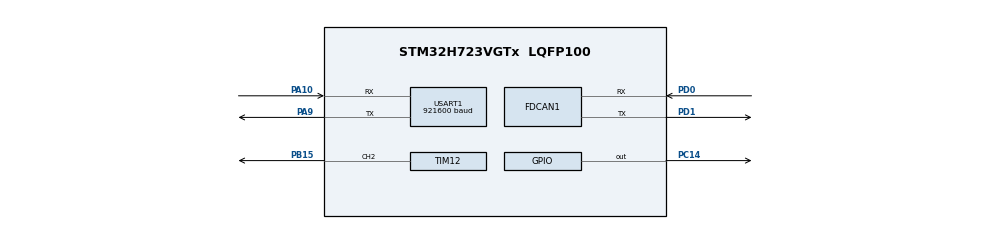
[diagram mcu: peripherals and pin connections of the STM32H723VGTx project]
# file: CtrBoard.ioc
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CORTEX_M7.CPU_DCache=Disabled
CORTEX_M7.CPU_ICache=Disabled
FDCAN1.AutoRetransmission=ENABLE
FDCAN1.CalculateBaudRateNominal=1000000
FDCAN1.CalculateTimeBitNominal=1000
FDCAN1.CalculateTimeQuantumNominal=12.5
FDCAN1.DataPrescaler=1
FDCAN1.DataSyncJumpWidth=2
FDCAN1.DataTimeSeg1=13
FDCAN1.DataTimeSeg2=2
FDCAN1.ExtFiltersNbr=4
FDCAN1.FrameFormat=FDCAN_FRAME_FD_BRS
FDCAN1.NominalPrescaler=1
FDCAN1.NominalSyncJumpWidth=3
FDCAN1.NominalTimeSeg1=63
FDCAN1.NominalTimeSeg2=16
FDCAN1.ProtocolException=ENABLE
FDCAN1.RxBufferSize=FDCAN_DATA_BYTES_64
FDCAN1.RxBuffersNbr=4
FDCAN1.RxFifo0ElmtSize=FDCAN_DATA_BYTES_64
FDCAN1.RxFifo0ElmtsNbr=1
FDCAN1.RxFifo1ElmtSize=FDCAN_DATA_BYTES_64
FDCAN1.RxFifo1ElmtsNbr=1
FDCAN1.StdFiltersNbr=4
FDCAN1.TxBuffersNbr=1
FDCAN1.TxElmtSize=FDCAN_DATA_BYTES_64
FDCAN1.TxEventsNbr=0
FDCAN1.TxFifoQueueElmtsNbr=1
Mcu.Family=STM32H7
Mcu.Name=STM32H723VGTx
Mcu.Package=LQFP100
NVIC.FDCAN1_IT0_IRQn=true\:0\:0\:false\:false\:true\:true\:true\:true
NVIC.FDCAN1_IT1_IRQn=true\:0\:0\:false\:false\:true\:true\:true\:true
NVIC.FDCAN_CAL_IRQn=true\:0\:0\:false\:false\:true\:true\:true\:true
NVIC.PriorityGroup=NVIC_PRIORITYGROUP_4
NVIC.TIM3_IRQn=true\:0\:0\:false\:false\:true\:true\:true\:true
NVIC.TIM4_IRQn=true\:0\:0\:false\:false\:true\:true\:true\:true
PA10.Mode=Asynchronous
PA10.Signal=USART1_RX
PA13(JTMS/SWDIO).Mode=Serial_Wire
PA13(JTMS/SWDIO).Signal=DEBUG_JTMS-SWDIO
PA14(JTCK/SWCLK).Mode=Serial_Wire
PA14(JTCK/SWCLK).Signal=DEBUG_JTCK-SWCLK
PA9.Mode=Asynchronous
PA9.Signal=USART1_TX
PB15.Signal=S_TIM12_CH2
PC14-OSC32_IN.Signal=GPIO_Output
PD0.Mode=FDCAN_Activate
PD0.Signal=FDCAN1_RX
PD1.Mode=FDCAN_Activate
PD1.Signal=FDCAN1_TX
PH0-OSC_IN.Mode=HSE-External-Oscillator
PH0-OSC_IN.Signal=RCC_OSC_IN
PH1-OSC_OUT.Mode=HSE-External-Oscillator
PH1-OSC_OUT.Signal=RCC_OSC_OUT
ProjectManager.HeapSize=0x2000
ProjectManager.StackSize=0x400
ProjectManager.TargetToolchain=MDK-ARM V5.32
RCC.ADCFreq_Value=48375000
RCC.APB1Freq_Value=120000000
RCC.APB2Freq_Value=120000000
RCC.APB3Freq_Value=120000000
RCC.APB4Freq_Value=120000000
RCC.CortexFreq_Value=480000000
RCC.D1PPRE=RCC_APB3_DIV2
RCC.D2PPRE1=RCC_APB1_DIV2
RCC.D2PPRE2=RCC_APB2_DIV2
RCC.D3PPRE=RCC_APB4_DIV2
RCC.DIVM1=2
RCC.DIVN1=40
RCC.DIVP1=1
RCC.DIVQ1=6
RCC.HCLKFreq_Value=240000000
RCC.HPRE=RCC_HCLK_DIV2
RCC.HSE_VALUE=24000000
RCC.PLLFRACN=0
RCC.PLLSourceVirtual=RCC_PLLSOURCE_HSE
RCC.RCC_MCO1Source=RCC_MCO1SOURCE_HSE
RCC.SYSCLKFreq_VALUE=480000000
RCC.SYSCLKSource=RCC_SYSCLKSOURCE_PLLCLK
RCC.USBCLockSelection=RCC_USBCLKSOURCE_HSI48
RCC.USBFreq_Value=48000000
SH.S_TIM12_CH2.0=TIM12_CH2,PWM Generation2 CH2
TIM12.Channel-PWM\ Generation2\ CH2=TIM_CHANNEL_2
TIM12.Period=2000-1
TIM12.Prescaler=24-1
TIM12.Pulse-PWM\ Generation2\ CH2=1000
TIM3.Period=1000-1
TIM3.Prescaler=240-1
TIM4.Period=1000-1
TIM4.Prescaler=240-1
USART1.BaudRate=921600
USART1.VirtualMode-Asynchronous=VM_ASYNC
VP_TIM3_VS_ClockSourceINT.Mode=Internal
VP_TIM4_VS_ClockSourceINT.Mode=Internal
board=custom

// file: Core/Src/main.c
/* USER CODE BEGIN Header */
/**
  ******************************************************************************
  * @file           : main.c
  * @brief          : Main program body
  ******************************************************************************
  * @attention
  *
  * Copyright (c) 2024 STMicroelectronics.
  * All rights reserved.
  *
  * This software is licensed under terms that can be found in the LICENSE file
  * in the root directory of this software component.
  * If no LICENSE file comes with this software, it is provided AS-IS.
  *
  ******************************************************************************
  */
/* USER CODE END Header */
#include "main.h"
#include "fdcan.h"
#include "tim.h"
#include "usart.h"
#include "gpio.h"

/* USER CODE BEGIN Includes */
#include "can_bsp.h"
/* USER CODE END Includes */

void SystemClock_Config(void);

/* USER CODE BEGIN 0 */
uint8_t data[12] = {1,2,3,4,5,6,7,8,9,10,11,12};
/* USER CODE END 0 */

int main(void)
{

  /* MCU Configuration--------------------------------------------------------*/

  /* Reset of all peripherals, Initializes the Flash interface and the Systick. */
  HAL_Init();

  /* Configure the system clock */
  SystemClock_Config();

  /* Initialize all configured peripherals */
  MX_GPIO_Init();
  MX_FDCAN1_Init();
  MX_TIM3_Init();
  MX_USART1_UART_Init();
  MX_TIM4_Init();
  MX_TIM12_Init();
  /* USER CODE BEGIN 2 */
	can_bsp_init();

  /* USER CODE END 2 */

  /* Infinite loop */
  /* USER CODE BEGIN WHILE */
  while (1)
  {
	  fdcanx_send_data(&hfdcan1, 0x520, data, 12);
	  HAL_Delay(500);
    /* USER CODE END WHILE */

  }
}

void SystemClock_Config(void)
{
  RCC_OscInitTypeDef RCC_OscInitStruct = {0};
  RCC_ClkInitTypeDef RCC_ClkInitStruct = {0};

  /** Supply configuration update enable
  */
  HAL_PWREx_ConfigSupply(PWR_LDO_SUPPLY);

  /** Configure the main internal regulator output voltage
  */
  __HAL_PWR_VOLTAGESCALING_CONFIG(PWR_REGULATOR_VOLTAGE_SCALE0);

  while(!__HAL_PWR_GET_FLAG(PWR_FLAG_VOSRDY)) {}

  /** Initializes the RCC Oscillators according to the specified parameters
  * in the RCC_OscInitTypeDef structure.
  */
  RCC_OscInitStruct.OscillatorType = RCC_OSCILLATORTYPE_HSE;
  RCC_OscInitStruct.HSEState = RCC_HSE_ON;
  RCC_OscInitStruct.PLL.PLLState = RCC_PLL_ON;
  RCC_OscInitStruct.PLL.PLLSource = RCC_PLLSOURCE_HSE;
  RCC_OscInitStruct.PLL.PLLM = 2;
  RCC_OscInitStruct.PLL.PLLN = 40;
  RCC_OscInitStruct.PLL.PLLP = 1;
  RCC_OscInitStruct.PLL.PLLQ = 6;
  RCC_OscInitStruct.PLL.PLLR = 2;
  RCC_OscInitStruct.PLL.PLLRGE = RCC_PLL1VCIRANGE_3;
  RCC_OscInitStruct.PLL.PLLVCOSEL = RCC_PLL1VCOWIDE;
  RCC_OscInitStruct.PLL.PLLFRACN = 0;
  if (HAL_RCC_OscConfig(&RCC_OscInitStruct) != HAL_OK)
  {
    Error_Handler();
  }

  /** Initializes the CPU, AHB and APB buses clocks
  */
  RCC_ClkInitStruct.ClockType = RCC_CLOCKTYPE_HCLK|RCC_CLOCKTYPE_SYSCLK
                              |RCC_CLOCKTYPE_PCLK1|RCC_CLOCKTYPE_PCLK2
                              |RCC_CLOCKTYPE_D3PCLK1|RCC_CLOCKTYPE_D1PCLK1;
  RCC_ClkInitStruct.SYSCLKSource = RCC_SYSCLKSOURCE_PLLCLK;
  RCC_ClkInitStruct.SYSCLKDivider = RCC_SYSCLK_DIV1;
  RCC_ClkInitStruct.AHBCLKDivider = RCC_HCLK_DIV2;
  RCC_ClkInitStruct.APB3CLKDivider = RCC_APB3_DIV2;
  RCC_ClkInitStruct.APB1CLKDivider = RCC_APB1_DIV2;
  RCC_ClkInitStruct.APB2CLKDivider = RCC_APB2_DIV2;
  RCC_ClkInitStruct.APB4CLKDivider = RCC_APB4_DIV2;

  if (HAL_RCC_ClockConfig(&RCC_ClkInitStruct, FLASH_LATENCY_3) != HAL_OK)
  {
    Error_Handler();
  }
}

void Error_Handler(void)
{
  __disable_irq();
  while (1)
  {
  }
}
